# HM1030 register map
File version: 0.1
HM1030 Microcontroller registers
Registers are 32-bit, read-write, reset 0x0 unless marked. A register's access mark holds for its fields unless they carry their own. Offsets are from the block's base; lines under a group give offsets from that group; [hi:lo] are bit positions; {n}, {i} and the like mark numbered series; 'fields as' and 'values as' point back to an identical list; <NAME> marks a mode.

## Memory map
0x40000000 SYS size 0x188 — Registers group
0x40000800 PMU size 0x84 — Registers group
0x40001000 DMA size 0x174 — Registers group
0x40003000 CRC size 0x10 — Registers group
0x40060000 GPIOA size 0x24 — Registers group
0x40060800 GPIOB size 0x24
0x40061000 GPIOC size 0x24 — Registers group
0x40064000 TIMERBASE0 size 0x38 — Registers group
0x40064800 TIMERBASE1 size 0x38
0x40065000 TIMERBASE2 size 0x38
0x40067000 TIMERPLUS0 size 0x44 — Registers group
0x40067800 TIMERPLUS1 size 0x44
0x40069000 RTC size 0x30 — Registers group
0x4006A000 IWDT size 0x14 — Registers group
0x4006A800 WWDT size 0x14 — Registers group
0x4006B000 UART0 size 0x24 — Registers group
0x4006B800 UART1 size 0x24
0x4006C000 UART2 size 0x24
0x4006F000 FLASH size 0x2C — Registers group
0x400B0000 PORT size 0x70C — Registers group
0x400B1000 PWMBASE0 size 0x44 — Registers group
0x400B1800 PWMBASE1 size 0x44
0x400B4000 PWMPLUS0 size 0xE8 — Registers group
0x400B4800 PWMPLUS1 size 0xE8
0x400B8000 SPI0 size 0x1C — Registers group
0x400B8800 SPI1 size 0x1C
0x400B9000 IIC0 size 0x38 — Registers group
0x400B9800 IIC1 size 0x38
0x400BA000 ADC size 0xF8 — Registers group
0x400BD000 AES size 0x30 — Registers group

## SYS — Registers group
Base 0x40000000
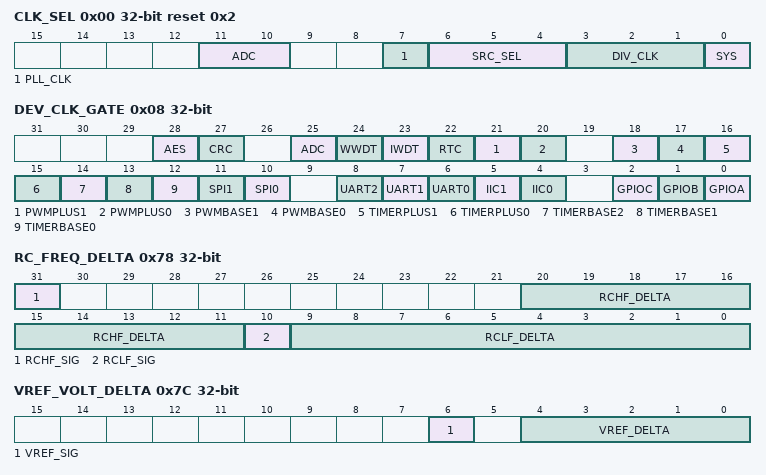
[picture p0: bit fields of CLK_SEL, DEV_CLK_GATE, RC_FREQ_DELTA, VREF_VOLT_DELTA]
0x00 CLK_SEL reset 0x2 — Clock Select
  [11:10] ADC — ADC 时钟选择 0 DIV1 1 DIV2 2 DIV4 3 DIV8
  [7] PLL_CLK — SRC 0 RCHF 1 XTAH
  [6:4] SRC_SEL — SRC 0 RCHF 1 RCLF 2 XTAH 3 XTAL 4 PLL
  [3:1] DIV_CLK — CLK_DIVx 0 DIV1 1 DIV2 2 DIV4 3 DIV8 4 DIV16 5 DIV32
  [0] SYS — 系统时钟选择 0 RCHF 1 CLK_DIV
0x04 DIV_CLK_GATE — Clock DIV Enable
  [0] DIV_EN
0x08 DEV_CLK_GATE — Clock Enable
  [28] AES, [27] CRC, [25] ADC, [24] WWDT, [23] IWDT, [22] RTC, [21] PWMPLUS1, [20] PWMPLUS0, [18] PWMBASE1, [17] PWMBASE0, [16] TIMERPLUS1, [15] TIMERPLUS0, [14] TIMERBASE2, [13] TIMERBASE1, [12] TIMERBASE0, [11] SPI1, [10] SPI0, [8] UART2, [7] UART1, [6] UART0, [5] IIC1, [4] IIC0, [2] GPIOC, [1] GPIOB, [0] GPIOA
0x78 RC_FREQ_DELTA — RC Register
  [31] RCHF_SIG — RCHF 符号 0 - 1 +
  [20:11] RCHF_DELTA — RCHF 差值
  [10] RCLF_SIG — RCLF 符号 0 - 1 +
  [9:0] RCLF_DELTA — RCLF 差值
0x7C VREF_VOLT_DELTA — RC Control Register
  [6] VREF_SIG — VREF 符号 0 - 1 +
  [4:0] VREF_DELTA — VREF 差值
{0x80+4i} CHIP_ID{i} (i=0..3)
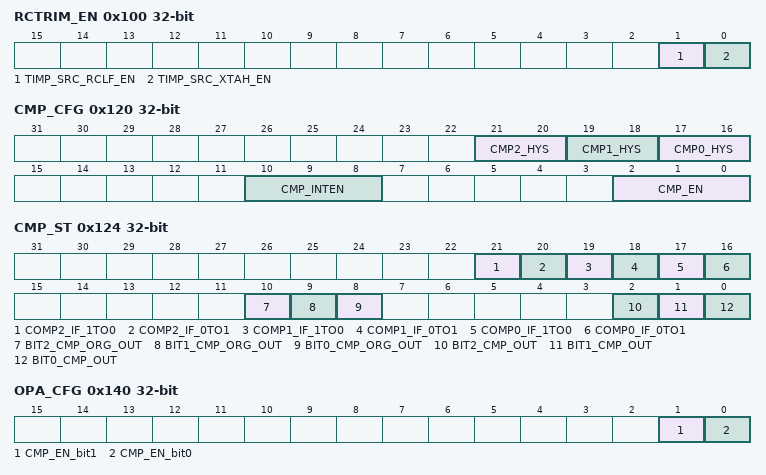
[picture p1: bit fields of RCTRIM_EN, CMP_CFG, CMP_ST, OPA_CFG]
0x100 RCTRIM_EN
  [1] TIMP_SRC_RCLF_EN, [0] TIMP_SRC_XTAH_EN
0x120 CMP_CFG
  [21:20] CMP2_HYS, [19:18] CMP1_HYS, [17:16] CMP0_HYS, [10:8] CMP_INTEN, [2:0] CMP_EN
0x124 CMP_ST
  [21] COMP2_IF_1TO0 — COMP0_IF
  [20] COMP2_IF_0TO1 — COMP0_IF
  [19] COMP1_IF_1TO0 — COMP0_IF
  [18] COMP1_IF_0TO1 — COMP0_IF
  [17] COMP0_IF_1TO0 — COMP0_IF
  [16] COMP0_IF_0TO1 — COMP0_IF
  [10] BIT2_CMP_ORG_OUT — CMP_OUT
  [9] BIT1_CMP_ORG_OUT — CMP_OUT
  [8] BIT0_CMP_ORG_OUT — CMP_OUT
  [2] BIT2_CMP_OUT — CMP_OUT
  [1] BIT1_CMP_OUT — CMP_OUT
  [0] BIT0_CMP_OUT — CMP_OUT
0x140 OPA_CFG
  [1] CMP_EN_bit1 — CMP_EN
  [0] CMP_EN_bit0 — CMP_EN

## PMU — Registers group
Base 0x40000800
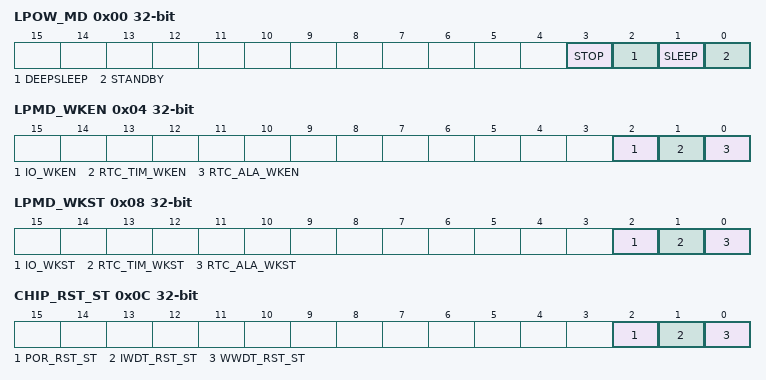
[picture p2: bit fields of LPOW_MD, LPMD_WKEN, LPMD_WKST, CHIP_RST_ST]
0x00 LPOW_MD — 低功耗模式选择寄存器
  [3] STOP — 写1，芯片进入STOP模式
  [2] DEEPSLEEP — 写1，芯片进入DEEPSLEEP模式
  [1] SLEEP — 写1，芯片进入SLEEP模式
  [0] STANDBY — 写1，芯片进入STANDBY模式
0x04 LPMD_WKEN — 低功耗唤醒源使能寄存器
  [2] IO_WKEN — 低功耗模式下，IO唤醒使能
  [1] RTC_TIM_WKEN — 低功耗模式下，RTC_TIM唤醒使能
  [0] RTC_ALA_WKEN — 低功耗模式下，RTC_ALA唤醒使能
0x08 LPMD_WKST — 低功耗唤醒源状态寄存器
  [2] IO_WKST — 低功耗模式下，IO唤醒标志
  [1] RTC_TIM_WKST — 低功耗模式下，RTC_TIM唤醒标志
  [0] RTC_ALA_WKST — 低功耗模式下，RTC_ALA唤醒标志
0x0C CHIP_RST_ST — 低功耗唤醒源标志寄存器
  [2] POR_RST_ST — 上电复位标志
  [1] IWDT_RST_ST — IWDT复位标志
  [0] WWDT_RST_ST — WWDT复位标志
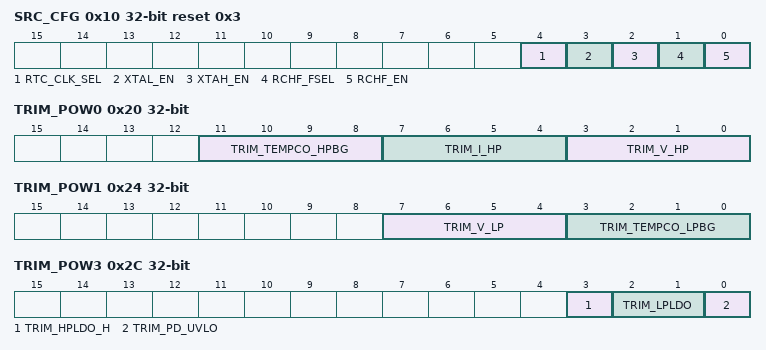
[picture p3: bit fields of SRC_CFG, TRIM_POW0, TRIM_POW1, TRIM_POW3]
0x10 SRC_CFG reset 0x3 — 时钟控制
  [4] RTC_CLK_SEL — RTC 时钟选择
  [3] XTAL_EN — XTAL 使能控制位
  [2] XTAH_EN — XTAH 使能控制位
  [1] RCHF_FSEL — RCHF 频率选择控制位
  [0] RCHF_EN — RCHF 使能控制位
0x20 TRIM_POW0 — 电压电流TRIM寄存器
  [11:8] TRIM_TEMPCO_HPBG — HPBG电压TRIM位
  [7:4] TRIM_I_HP — HPBG电压TRIM位
  [3:0] TRIM_V_HP — HPBG温度TRIM位
0x24 TRIM_POW1 — 电压电流TRIM寄存器
  [7:4] TRIM_V_LP — LPBG电压trim位
  [3:0] TRIM_TEMPCO_LPBG — LPBG温度trim位
0x28 TRIM_POW2 — TRIM寄存器
0x2C TRIM_POW3 — TRIM寄存器
  [3] TRIM_HPLDO_H — HPLDO电压调整到1.264v
  [2:1] TRIM_LPLDO — LPLDO电压输出trim位
  [0] TRIM_PD_UVLO — UVLO33trim位
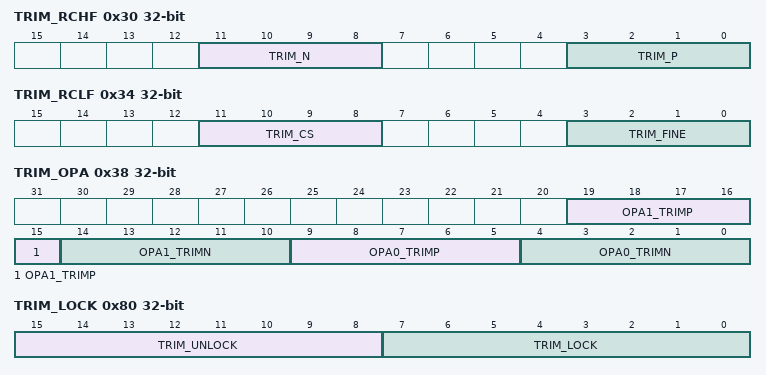
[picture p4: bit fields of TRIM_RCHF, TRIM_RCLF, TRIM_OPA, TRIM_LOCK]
0x30 TRIM_RCHF — TRIM寄存器
  [11:8] TRIM_N — RCHF_N_trim位
  [3:0] TRIM_P — RCHF_P_trim位
0x34 TRIM_RCLF — TRIM寄存器
  [11:8] TRIM_CS — RCLF_CS_trim位（粗调位）
  [3:0] TRIM_FINE — RCLF_FINE_trim位（精调位）
0x38 TRIM_OPA — TRIM寄存器
  [19:15] OPA1_TRIMP — OPA1的P端TRIM位
  [14:10] OPA1_TRIMN — OPA1的N端TRIM位
  [9:5] OPA0_TRIMP — OPA0的P端TRIM位
  [4:0] OPA0_TRIMN — OPA0的N端TRIM位
0x3C TRIM_PLL — TRIM寄存器
  [3:0] PLL_R_TRSIM — PLL的R值TRIM位
0x80 TRIM_LOCK — TRIM锁定寄存器
  [15:8] TRIM_UNLOCK — 写入0xAA,TRIM_POW和TRIM_RC能被改写
  [7:0] TRIM_LOCK — 写入0x55,TRIM_POW和TRIM_RC不能被改写
